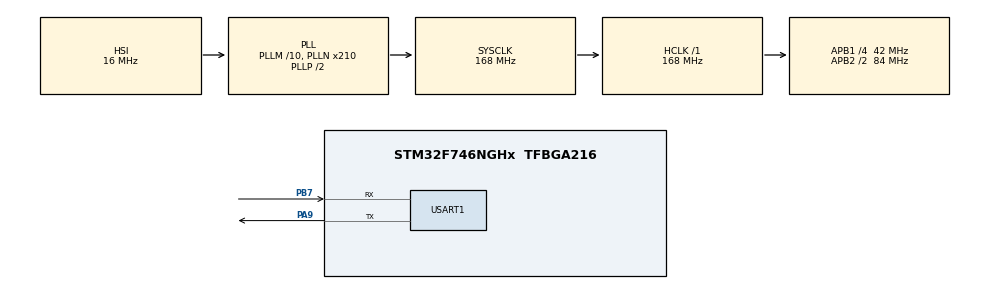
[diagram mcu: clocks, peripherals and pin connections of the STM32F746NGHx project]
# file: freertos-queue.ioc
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Mcu.Family=STM32F7
RCC.PLLSourceVirtual=RCC_PLLSOURCE_HSI
FREERTOS.Queues01=myQueue1,5,uint8_t,0,Dynamic,NULL,NULL
VP_SYS_VS_tim6.Mode=TIM6
RCC.CortexFreq_Value=168000000
FREERTOS.Tasks01=Task1,0,128,StartTask1,Default,NULL,Dynamic,NULL,NULL;myTask2,0,128,StartTask2,Default,NULL,Dynamic,NULL,NULL
NVIC.TIM6_DAC_IRQn=true\:0\:0\:false\:false\:true\:false\:false\:true
RCC.APB1CLKDivider=RCC_HCLK_DIV4
RCC.SYSCLKSource=RCC_SYSCLKSOURCE_PLLCLK
ProjectManager.StackSize=0x400
USART1.VirtualMode-Asynchronous=VM_ASYNC
PA9.Mode=Asynchronous
ProjectManager.TargetToolchain=STM32CubeIDE
RCC.HCLKFreq_Value=168000000
RCC.APB2TimFreq_Value=168000000
PA9.Signal=USART1_TX
RCC.USBFreq_Value=168000000
RCC.LSE_VALUE=32768
RCC.AHBFreq_Value=168000000
RCC.HSE_VALUE=25000000
board=STM32F746G-DISCO
RCC.VCOOutputFreq_Value=336000000
RCC.APB2Freq_Value=84000000
PB7.Signal=USART1_RX
VP_FREERTOS_VS_CMSIS_V1.Mode=CMSIS_V1
Mcu.Name=STM32F746NGHx
RCC.SYSCLKFreq_VALUE=168000000
Mcu.Package=TFBGA216
NVIC.TimeBase=TIM6_DAC_IRQn
PB7.Mode=Asynchronous
NVIC.TimeBaseIP=TIM6
ProjectManager.HeapSize=0x200
RCC.HSI_VALUE=16000000
NVIC.PriorityGroup=NVIC_PRIORITYGROUP_4
RCC.APB2CLKDivider=RCC_HCLK_DIV2
RCC.PLLM=10
RCC.PLLN=210
RCC.APB1TimFreq_Value=84000000
RCC.APB1Freq_Value=42000000

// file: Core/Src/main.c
/* USER CODE BEGIN Header */
/**
  ******************************************************************************
  * @file           : main.c
  * @brief          : Main program body
  ******************************************************************************
  * @attention
  *
  * <h2><center>&copy; Copyright (c) 2021 STMicroelectronics.
  * All rights reserved.</center></h2>
  *
  * This software component is licensed by ST under Ultimate Liberty license
  * SLA0044, the "License"; You may not use this file except in compliance with
  * the License. You may obtain a copy of the License at:
  *                             www.st.com/SLA0044
  *
  ******************************************************************************
  */
/* USER CODE END Header */
#include "main.h"
#include "cmsis_os.h"

/* USER CODE BEGIN Includes */
#include <stdio.h>
/* USER CODE END Includes */

UART_HandleTypeDef huart1;

osThreadId Task1Handle;
osThreadId myTask2Handle;
osMessageQId myQueue1Handle;
/* USER CODE BEGIN PV */
uint8_t queue_data;
/* USER CODE END PV */

void SystemClock_Config(void);
static void MX_GPIO_Init(void);
static void MX_USART1_UART_Init(void);
void StartTask1(void const * argument);
void StartTask2(void const * argument);

/* USER CODE BEGIN 0 */
int _write(int file, char *ptr, int len)
{
	HAL_UART_Transmit(&huart1,(uint8_t *)ptr,len,10);
	return len;
}
/* USER CODE END 0 */

int main(void)
{
  /* USER CODE BEGIN 1 */
  queue_data = 1;
  /* USER CODE END 1 */

  /* MCU Configuration--------------------------------------------------------*/

  /* Reset of all peripherals, Initializes the Flash interface and the Systick. */
  HAL_Init();

  /* Configure the system clock */
  SystemClock_Config();

  /* Initialize all configured peripherals */
  MX_GPIO_Init();
  MX_USART1_UART_Init();

  /* Create the queue(s) */
  /* definition and creation of myQueue1 */
  osMessageQDef(myQueue1, 5, uint8_t);
  myQueue1Handle = osMessageCreate(osMessageQ(myQueue1), NULL);

  /* Create the thread(s) */
  /* definition and creation of Task1 */
  osThreadDef(Task1, StartTask1, osPriorityNormal, 0, 128);
  Task1Handle = osThreadCreate(osThread(Task1), NULL);

  /* definition and creation of myTask2 */
  osThreadDef(myTask2, StartTask2, osPriorityNormal, 0, 128);
  myTask2Handle = osThreadCreate(osThread(myTask2), NULL);

  /* Start scheduler */
  osKernelStart();

  /* We should never get here as control is now taken by the scheduler */
  /* Infinite loop */
  while (1)
  {

  }
}

void SystemClock_Config(void)
{
  RCC_OscInitTypeDef RCC_OscInitStruct = {0};
  RCC_ClkInitTypeDef RCC_ClkInitStruct = {0};
  RCC_PeriphCLKInitTypeDef PeriphClkInitStruct = {0};

  /** Configure the main internal regulator output voltage
  */
  __HAL_RCC_PWR_CLK_ENABLE();
  __HAL_PWR_VOLTAGESCALING_CONFIG(PWR_REGULATOR_VOLTAGE_SCALE2);
  /** Initializes the RCC Oscillators according to the specified parameters
  * in the RCC_OscInitTypeDef structure.
  */
  RCC_OscInitStruct.OscillatorType = RCC_OSCILLATORTYPE_HSI;
  RCC_OscInitStruct.HSIState = RCC_HSI_ON;
  RCC_OscInitStruct.HSICalibrationValue = RCC_HSICALIBRATION_DEFAULT;
  RCC_OscInitStruct.PLL.PLLState = RCC_PLL_ON;
  RCC_OscInitStruct.PLL.PLLSource = RCC_PLLSOURCE_HSI;
  RCC_OscInitStruct.PLL.PLLM = 10;
  RCC_OscInitStruct.PLL.PLLN = 210;
  RCC_OscInitStruct.PLL.PLLP = RCC_PLLP_DIV2;
  RCC_OscInitStruct.PLL.PLLQ = 2;
  if (HAL_RCC_OscConfig(&RCC_OscInitStruct) != HAL_OK)
  {
    Error_Handler();
  }
  /** Initializes the CPU, AHB and APB buses clocks
  */
  RCC_ClkInitStruct.ClockType = RCC_CLOCKTYPE_HCLK|RCC_CLOCKTYPE_SYSCLK
                              |RCC_CLOCKTYPE_PCLK1|RCC_CLOCKTYPE_PCLK2;
  RCC_ClkInitStruct.SYSCLKSource = RCC_SYSCLKSOURCE_PLLCLK;
  RCC_ClkInitStruct.AHBCLKDivider = RCC_SYSCLK_DIV1;
  RCC_ClkInitStruct.APB1CLKDivider = RCC_HCLK_DIV4;
  RCC_ClkInitStruct.APB2CLKDivider = RCC_HCLK_DIV2;

  if (HAL_RCC_ClockConfig(&RCC_ClkInitStruct, FLASH_LATENCY_5) != HAL_OK)
  {
    Error_Handler();
  }
  PeriphClkInitStruct.PeriphClockSelection = RCC_PERIPHCLK_USART1;
  PeriphClkInitStruct.Usart1ClockSelection = RCC_USART1CLKSOURCE_PCLK2;
  if (HAL_RCCEx_PeriphCLKConfig(&PeriphClkInitStruct) != HAL_OK)
  {
    Error_Handler();
  }
}

static void MX_USART1_UART_Init(void)
{

  huart1.Instance = USART1;
  huart1.Init.BaudRate = 115200;
  huart1.Init.WordLength = UART_WORDLENGTH_8B;
  huart1.Init.StopBits = UART_STOPBITS_1;
  huart1.Init.Parity = UART_PARITY_NONE;
  huart1.Init.Mode = UART_MODE_TX_RX;
  huart1.Init.HwFlowCtl = UART_HWCONTROL_NONE;
  huart1.Init.OverSampling = UART_OVERSAMPLING_16;
  huart1.Init.OneBitSampling = UART_ONE_BIT_SAMPLE_DISABLE;
  huart1.AdvancedInit.AdvFeatureInit = UART_ADVFEATURE_NO_INIT;
  if (HAL_UART_Init(&huart1) != HAL_OK)
  {
    Error_Handler();
  }

}

static void MX_GPIO_Init(void)
{

  /* GPIO Ports Clock Enable */
  __HAL_RCC_GPIOB_CLK_ENABLE();
  __HAL_RCC_GPIOA_CLK_ENABLE();

}

void StartTask1(void const * argument)
{
  /* USER CODE BEGIN 5 */
	osStatus retvalue;
  /* Infinite loop */
  for(;;)
  {
	  printf("T1: queue put task\r\n");
	  retvalue = osMessagePut(myQueue1Handle, queue_data, 200);
	  if (retvalue == osOK)
	  {
		  printf("T1: queue put success\r\n");
		  queue_data++;
	  }
	  else
	  {
		  printf("T1: queue put fail\r\n");
	  }
      osDelay(1000);
  }
  /* USER CODE END 5 */
}

void StartTask2(void const * argument)
{
  /* USER CODE BEGIN StartTask2 */
  osEvent retstatus;
  /* Infinite loop */
  for(;;)
  {
	  osDelay(7000);
	  printf("T2: Queue get task\r\n");
	  retstatus = osMessageGet(myQueue1Handle, 200);
	  printf("T2 Data: %d\r\n", (uint8_t)retstatus.value.v);
  }
  /* USER CODE END StartTask2 */
}

 /**
  * @brief  Period elapsed callback in non blocking mode
  * @note   This function is called  when TIM6 interrupt took place, inside
  * HAL_TIM_IRQHandler(). It makes a direct call to HAL_IncTick() to increment
  * a global variable "uwTick" used as application time base.
  * @param  htim : TIM handle
  * @retval None
  */
void HAL_TIM_PeriodElapsedCallback(TIM_HandleTypeDef *htim)
{
  if (htim->Instance == TIM6) {
    HAL_IncTick();
  }
}

void Error_Handler(void)
{
}

/************************ (C) COPYRIGHT STMicroelectronics *****END OF FILE****/
